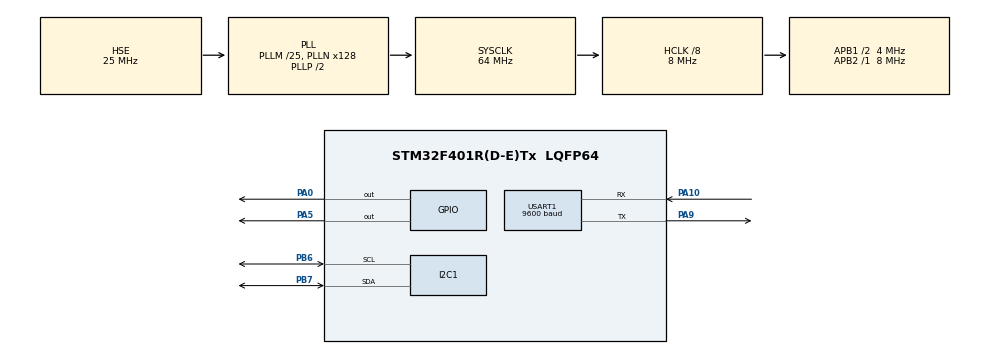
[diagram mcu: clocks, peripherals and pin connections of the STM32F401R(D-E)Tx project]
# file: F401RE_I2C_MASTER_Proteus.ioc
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I2C1.I2C_Mode=I2C_Fast
I2C1.OwnAddress=0
Mcu.Family=STM32F4
Mcu.Name=STM32F401R(D-E)Tx
Mcu.Package=LQFP64
NVIC.PriorityGroup=NVIC_PRIORITYGROUP_4
PA0-WKUP.Signal=GPIO_Output
PA10.Mode=Asynchronous
PA10.Signal=USART1_RX
PA5.Signal=GPIO_Output
PA9.Mode=Asynchronous
PA9.Signal=USART1_TX
PB6.Mode=I2C
PB6.Signal=I2C1_SCL
PB7.Mode=I2C
PB7.Signal=I2C1_SDA
PH0\ -\ OSC_IN.Mode=HSE-External-Oscillator
PH0\ -\ OSC_IN.Signal=RCC_OSC_IN
PH1\ -\ OSC_OUT.Mode=HSE-External-Oscillator
PH1\ -\ OSC_OUT.Signal=RCC_OSC_OUT
ProjectManager.HeapSize=0x200
ProjectManager.StackSize=0x400
ProjectManager.TargetToolchain=STM32CubeIDE
RCC.48MHZClocksFreq_Value=32000000
RCC.AHBCLKDivider=RCC_SYSCLK_DIV8
RCC.AHBFreq_Value=8000000
RCC.APB1CLKDivider=RCC_HCLK_DIV2
RCC.APB1Freq_Value=4000000
RCC.APB1TimFreq_Value=8000000
RCC.APB2Freq_Value=8000000
RCC.APB2TimFreq_Value=8000000
RCC.CortexFreq_Value=8000000
RCC.HCLKFreq_Value=8000000
RCC.HSE_VALUE=25000000
RCC.HSI_VALUE=16000000
RCC.LSE_VALUE=32768
RCC.PLLM=25
RCC.PLLN=128
RCC.PLLSourceVirtual=RCC_PLLSOURCE_HSE
RCC.SYSCLKFreq_VALUE=64000000
RCC.SYSCLKSource=RCC_SYSCLKSOURCE_PLLCLK
RCC.VCOOutputFreq_Value=128000000
USART1.BaudRate=9600
USART1.VirtualMode=VM_ASYNC
board=custom

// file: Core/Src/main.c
/* USER CODE BEGIN Header */
/**
  ******************************************************************************
  * @file           : main.c
  * @brief          : Main program body
  ******************************************************************************
  * @attention
  *
  * Copyright (c) 2024 STMicroelectronics.
  * All rights reserved.
  *
  * This software is licensed under terms that can be found in the LICENSE file
  * in the root directory of this software component.
  * If no LICENSE file comes with this software, it is provided AS-IS.
  *
  ******************************************************************************
  */
/* USER CODE END Header */
#include "main.h"

/* USER CODE BEGIN Includes */

#include <string.h>
#include <stdio.h>

/* USER CODE END Includes */

/* USER CODE BEGIN PD */
#define SLAVE_ADDRESS   0x20<<1
#define EEPROM_ADDRESS  0xA0

/* USER CODE END PD */

I2C_HandleTypeDef hi2c1;

UART_HandleTypeDef huart1;

void SystemClock_Config(void);
static void MX_GPIO_Init(void);
static void MX_I2C1_Init(void);
static void MX_USART1_UART_Init(void);

/* USER CODE BEGIN 0 */
//uint8_t RData[5];

//void EEPROM_WriteByte(uint16_t address,uint8_t data)
//{
//	uint8_t TxBuffer[2];
//	TxBuffer[0] = address >> 8;
//	TxBuffer[1] = address & 0xFF;
//	TxBuffer[2] = data;
//
//	HAL_I2C_Master_Transmit(&hi2c1, EEPROM_ADDRESS, TxBuffer, 3, HAL_MAX_DELAY);
//	HAL_Delay(100);
//
//}

//uint8_t  EEPROM_ReadByte(uint16_t address)
//{
//	uint8_t RxBuffer[2];
//	RxBuffer[0] = address >> 8;
//	RxBuffer[1] = address & 0xFF;
//
//
//	HAL_I2C_Master_Transmit(&hi2c1, EEPROM_ADDRESS | 0x00, RxBuffer, 2, HAL_MAX_DELAY);
//	HAL_Delay(10);
//	HAL_I2C_Master_Receive(&hi2c1, EEPROM_ADDRESS | 0x01, RxBuffer, 1, HAL_MAX_DELAY);
//	HAL_Delay(10);
//
//	return RxBuffer[0];
//}
/* USER CODE END 0 */

int main(void)
{

  /* MCU Configuration--------------------------------------------------------*/

  /* Reset of all peripherals, Initializes the Flash interface and the Systick. */
  HAL_Init();

  /* Configure the system clock */
  SystemClock_Config();

  /* Initialize all configured peripherals */
  MX_GPIO_Init();
  MX_I2C1_Init();
  MX_USART1_UART_Init();
  /* USER CODE BEGIN 2 */
//  uint8_t rdata[5]={0};
  /* USER CODE END 2 */

  /* Infinite loop */
  /* USER CODE BEGIN WHILE */
  while (1)
  {

//	  HAL_I2C_Mem_Write(&hi2c1, 0xA0, 0x0000, 5,(uint8_t *) "Hello", 5, HAL_MAX_DELAY);
//	  HAL_Delay(100);
//	  HAL_I2C_Mem_Read(&hi2c1, 0xA0, 0x0000, 5, rdata, 5, HAL_MAX_DELAY);
//	  HAL_Delay(100);
//	for(uint8_t i=0; i<255;i++)
//	{
//
		HAL_I2C_Master_Transmit(&hi2c1, SLAVE_ADDRESS,(uint8_t *) "HELLO", 5, HAL_MAX_DELAY);
		HAL_Delay(1000);
//	}
//	  EEPROM_WriteByte(0x0000,'A');
//	  HAL_Delay(1000);
//	  uint8_t rxdata = EEPROM_ReadByte(0x0000);
//	  HAL_I2C_Master_Transmit(&hi2c1, SLAVE_ADDRESS, &rxdata, 1, HAL_MAX_DELAY);
	  //HAL_I2C_Master_Transmit(&hi2c1, 0x20,(uint8_t *) "Hello", 5, HAL_MAX_DELAY);
//	  if(HAL_UART_Transmit(&huart1,(uint8_t *) "Done Sending..\r\n", 16, HAL_MAX_DELAY) != HAL_OK)
//	  {
//		  HAL_GPIO_WritePin(GPIOA, GPIO_PIN_5, 1);
//		  HAL_Delay(1000);
//		  HAL_GPIO_WritePin(GPIOA, GPIO_PIN_5, 0);
//		  HAL_Delay(1000);
//
//		  Error_Handler();
//	  }
//	  HAL_Delay(1000);

//	  for(uint8_t i=0;i<5;i++)
//	  {
//		  HAL_I2C_Master_Transmit(&hi2c1, SLAVE_ADDRESS, &RData[i], 1, HAL_MAX_DELAY);
//		  HAL_Delay(1000);
//	  }
    /* USER CODE END WHILE */

  }
}

void SystemClock_Config(void)
{
  RCC_OscInitTypeDef RCC_OscInitStruct = {0};
  RCC_ClkInitTypeDef RCC_ClkInitStruct = {0};

  /** Configure the main internal regulator output voltage
  */
  __HAL_RCC_PWR_CLK_ENABLE();
  __HAL_PWR_VOLTAGESCALING_CONFIG(PWR_REGULATOR_VOLTAGE_SCALE2);

  /** Initializes the RCC Oscillators according to the specified parameters
  * in the RCC_OscInitTypeDef structure.
  */
  RCC_OscInitStruct.OscillatorType = RCC_OSCILLATORTYPE_HSE;
  RCC_OscInitStruct.HSEState = RCC_HSE_ON;
  RCC_OscInitStruct.PLL.PLLState = RCC_PLL_ON;
  RCC_OscInitStruct.PLL.PLLSource = RCC_PLLSOURCE_HSE;
  RCC_OscInitStruct.PLL.PLLM = 25;
  RCC_OscInitStruct.PLL.PLLN = 128;
  RCC_OscInitStruct.PLL.PLLP = RCC_PLLP_DIV2;
  RCC_OscInitStruct.PLL.PLLQ = 4;
  if (HAL_RCC_OscConfig(&RCC_OscInitStruct) != HAL_OK)
  {
    Error_Handler();
  }

  /** Initializes the CPU, AHB and APB buses clocks
  */
  RCC_ClkInitStruct.ClockType = RCC_CLOCKTYPE_HCLK|RCC_CLOCKTYPE_SYSCLK
                              |RCC_CLOCKTYPE_PCLK1|RCC_CLOCKTYPE_PCLK2;
  RCC_ClkInitStruct.SYSCLKSource = RCC_SYSCLKSOURCE_PLLCLK;
  RCC_ClkInitStruct.AHBCLKDivider = RCC_SYSCLK_DIV8;
  RCC_ClkInitStruct.APB1CLKDivider = RCC_HCLK_DIV2;
  RCC_ClkInitStruct.APB2CLKDivider = RCC_HCLK_DIV1;

  if (HAL_RCC_ClockConfig(&RCC_ClkInitStruct, FLASH_LATENCY_0) != HAL_OK)
  {
    Error_Handler();
  }
}

static void MX_I2C1_Init(void)
{

  hi2c1.Instance = I2C1;
  hi2c1.Init.ClockSpeed = 400000;
  hi2c1.Init.DutyCycle = I2C_DUTYCYCLE_2;
  hi2c1.Init.OwnAddress1 = 0;
  hi2c1.Init.AddressingMode = I2C_ADDRESSINGMODE_7BIT;
  hi2c1.Init.DualAddressMode = I2C_DUALADDRESS_DISABLE;
  hi2c1.Init.OwnAddress2 = 0;
  hi2c1.Init.GeneralCallMode = I2C_GENERALCALL_DISABLE;
  hi2c1.Init.NoStretchMode = I2C_NOSTRETCH_DISABLE;
  if (HAL_I2C_Init(&hi2c1) != HAL_OK)
  {
    Error_Handler();
  }

}

static void MX_USART1_UART_Init(void)
{

  huart1.Instance = USART1;
  huart1.Init.BaudRate = 9600;
  huart1.Init.WordLength = UART_WORDLENGTH_8B;
  huart1.Init.StopBits = UART_STOPBITS_1;
  huart1.Init.Parity = UART_PARITY_NONE;
  huart1.Init.Mode = UART_MODE_TX_RX;
  huart1.Init.HwFlowCtl = UART_HWCONTROL_NONE;
  huart1.Init.OverSampling = UART_OVERSAMPLING_16;
  if (HAL_UART_Init(&huart1) != HAL_OK)
  {
    Error_Handler();
  }

}

static void MX_GPIO_Init(void)
{
  GPIO_InitTypeDef GPIO_InitStruct = {0};

  /* GPIO Ports Clock Enable */
  __HAL_RCC_GPIOH_CLK_ENABLE();
  __HAL_RCC_GPIOA_CLK_ENABLE();
  __HAL_RCC_GPIOB_CLK_ENABLE();

  /*Configure GPIO pin Output Level */
  HAL_GPIO_WritePin(GPIOA, GPIO_PIN_0|GPIO_PIN_5, GPIO_PIN_RESET);

  /*Configure GPIO pins : PA0 PA5 */
  GPIO_InitStruct.Pin = GPIO_PIN_0|GPIO_PIN_5;
  GPIO_InitStruct.Mode = GPIO_MODE_OUTPUT_PP;
  GPIO_InitStruct.Pull = GPIO_NOPULL;
  GPIO_InitStruct.Speed = GPIO_SPEED_FREQ_LOW;
  HAL_GPIO_Init(GPIOA, &GPIO_InitStruct);

}

void Error_Handler(void)
{
  __disable_irq();
  while (1)
  {
  }
}
